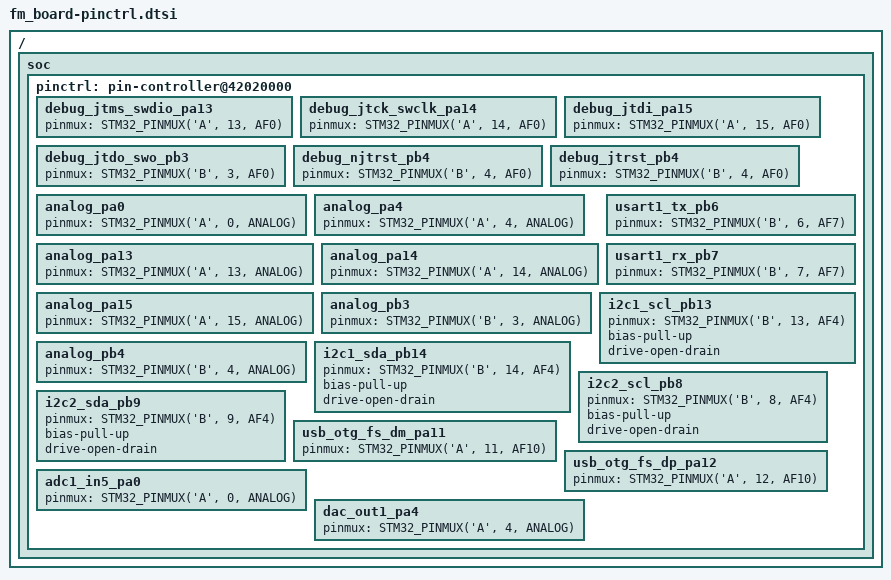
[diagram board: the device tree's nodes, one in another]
/*
 * Copyright (c) 2025 OE5XRX
 * SPDX-License-Identifier: LGPL-3.0-or-later
 *
 * FM Board Pin Control Device Tree
 * Pin assignments for STM32U575CITx microcontroller
 */

#include <zephyr/dt-bindings/pinctrl/stm32-pinctrl.h>

/ {
	soc {
		pinctrl: pin-controller@42020000 {
			/* Debug/JTAG/SWD - Required by swj_port in base DTS */
			/omit-if-no-ref/ debug_jtms_swdio_pa13: debug_jtms_swdio_pa13 {
				pinmux = <STM32_PINMUX('A', 13, AF0)>;
			};
			/omit-if-no-ref/ debug_jtck_swclk_pa14: debug_jtck_swclk_pa14 {
				pinmux = <STM32_PINMUX('A', 14, AF0)>;
			};
			/omit-if-no-ref/ debug_jtdi_pa15: debug_jtdi_pa15 {
				pinmux = <STM32_PINMUX('A', 15, AF0)>;
			};
			/omit-if-no-ref/ debug_jtdo_swo_pb3: debug_jtdo_swo_pb3 {
				pinmux = <STM32_PINMUX('B', 3, AF0)>;
			};
			/omit-if-no-ref/ debug_njtrst_pb4: debug_njtrst_pb4 {
				pinmux = <STM32_PINMUX('B', 4, AF0)>;
			};
			/omit-if-no-ref/ debug_jtrst_pb4: debug_jtrst_pb4 {
				pinmux = <STM32_PINMUX('B', 4, AF0)>;
			};

			/* Sleep mode analog pins */
			/omit-if-no-ref/ analog_pa0: analog_pa0 {
				pinmux = <STM32_PINMUX('A', 0, ANALOG)>;
			};
			/omit-if-no-ref/ analog_pa4: analog_pa4 {
				pinmux = <STM32_PINMUX('A', 4, ANALOG)>;
			};
			/omit-if-no-ref/ analog_pa13: analog_pa13 {
				pinmux = <STM32_PINMUX('A', 13, ANALOG)>;
			};
			/omit-if-no-ref/ analog_pa14: analog_pa14 {
				pinmux = <STM32_PINMUX('A', 14, ANALOG)>;
			};
			/omit-if-no-ref/ analog_pa15: analog_pa15 {
				pinmux = <STM32_PINMUX('A', 15, ANALOG)>;
			};
			/omit-if-no-ref/ analog_pb3: analog_pb3 {
				pinmux = <STM32_PINMUX('B', 3, ANALOG)>;
			};
			/omit-if-no-ref/ analog_pb4: analog_pb4 {
				pinmux = <STM32_PINMUX('B', 4, ANALOG)>;
			};

			/* USART1: PB6 (TX) / PB7 (RX) */
			/omit-if-no-ref/ usart1_tx_pb6: usart1_tx_pb6 {
				pinmux = <STM32_PINMUX('B', 6, AF7)>;
			};
			/omit-if-no-ref/ usart1_rx_pb7: usart1_rx_pb7 {
				pinmux = <STM32_PINMUX('B', 7, AF7)>;
			};

			/* I2C1: PB13 (SCL) / PB14 (SDA) */
			/omit-if-no-ref/ i2c1_scl_pb13: i2c1_scl_pb13 {
				pinmux = <STM32_PINMUX('B', 13, AF4)>;
				bias-pull-up;
				drive-open-drain;
			};
			/omit-if-no-ref/ i2c1_sda_pb14: i2c1_sda_pb14 {
				pinmux = <STM32_PINMUX('B', 14, AF4)>;
				bias-pull-up;
				drive-open-drain;
			};

			/* I2C2: PB8 (SCL) / PB9 (SDA) */
			/omit-if-no-ref/ i2c2_scl_pb8: i2c2_scl_pb8 {
				pinmux = <STM32_PINMUX('B', 8, AF4)>;
				bias-pull-up;
				drive-open-drain;
			};
			/omit-if-no-ref/ i2c2_sda_pb9: i2c2_sda_pb9 {
				pinmux = <STM32_PINMUX('B', 9, AF4)>;
				bias-pull-up;
				drive-open-drain;
			};

			/* USB OTG FS: PA11 (DM) / PA12 (DP) */
			/omit-if-no-ref/ usb_otg_fs_dm_pa11: usb_otg_fs_dm_pa11 {
				pinmux = <STM32_PINMUX('A', 11, AF10)>;
			};
			/omit-if-no-ref/ usb_otg_fs_dp_pa12: usb_otg_fs_dp_pa12 {
				pinmux = <STM32_PINMUX('A', 12, AF10)>;
			};

			/* ADC1: PA0 (Channel 5) */
			/omit-if-no-ref/ adc1_in5_pa0: adc1_in5_pa0 {
				pinmux = <STM32_PINMUX('A', 0, ANALOG)>;
			};

			/* DAC1: PA4 (Output 1) */
			/omit-if-no-ref/ dac_out1_pa4: dac_out1_pa4 {
				pinmux = <STM32_PINMUX('A', 4, ANALOG)>;
			};
		};
	};
};
